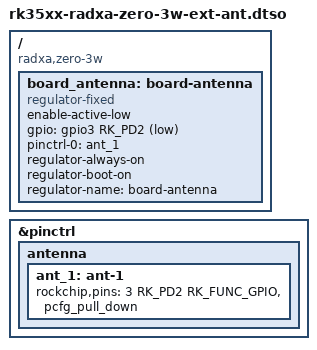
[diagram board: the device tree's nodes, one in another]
/dts-v1/;
/plugin/;

#include <dt-bindings/gpio/gpio.h>
#include <dt-bindings/pinctrl/rockchip.h>

/ {
	compatible = "radxa,zero-3w", "rockchip,rk3566";

	fragment@0 {
		target-path = "/";
			__overlay__ {
			board_antenna: board-antenna {
				compatible = "regulator-fixed";
				enable-active-low;
				gpio = <&gpio3 RK_PD2 GPIO_ACTIVE_LOW>;
				pinctrl-0 = <&ant_1>;
				pinctrl-names = "default";
				regulator-always-on;
				regulator-boot-on;
				regulator-name = "board-antenna";
				status = "okay";
			};
		};
	};

	fragment@1 {
		target = <&pinctrl>;
			__overlay__ {
			antenna {
				ant_1: ant-1 {
					rockchip,pins = <3 RK_PD2 RK_FUNC_GPIO &pcfg_pull_down>;
				};
			};
		};
	};
};
